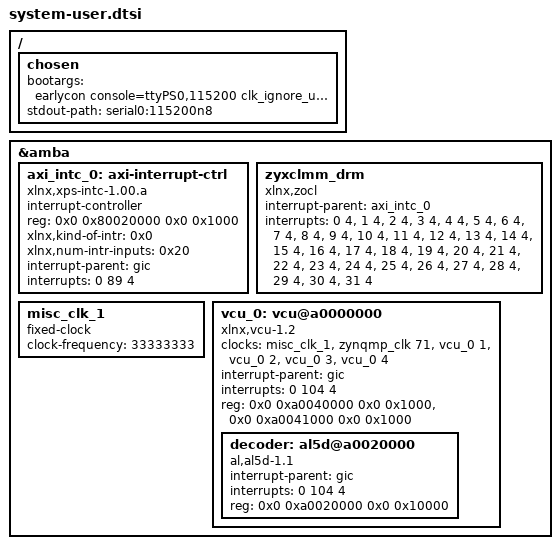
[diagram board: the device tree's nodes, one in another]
/include/ "system-conf.dtsi"
/ {
	chosen {
		bootargs = "earlycon console=ttyPS0,115200 clk_ignore_unused root=/dev/mmcblk0p2 rw rootwait cma=1200M";
		stdout-path = "serial0:115200n8";
	};
};
&amba {
	axi_intc_0: axi-interrupt-ctrl {
		#interrupt-cells = <2>;
		compatible = "xlnx,xps-intc-1.00.a";
		interrupt-controller;
		reg = <0x0 0x80020000 0x0 0x1000>;
		xlnx,kind-of-intr = <0x0>;
		xlnx,num-intr-inputs = <0x20>;
		interrupt-parent = <&gic>;
		interrupts = <0 89 4>;
	};

	zyxclmm_drm {
		compatible = "xlnx,zocl";
		status = "okay";
		interrupt-parent = <&axi_intc_0>;
		interrupts = <0  4>, <1  4>, <2  4>, <3  4>,
			     <4  4>, <5  4>, <6  4>, <7  4>,
			     <8  4>, <9  4>, <10 4>, <11 4>,
			     <12 4>, <13 4>, <14 4>, <15 4>,
			     <16 4>, <17 4>, <18 4>, <19 4>,
			     <20 4>, <21 4>, <22 4>, <23 4>,
			     <24 4>, <25 4>, <26 4>, <27 4>,
			     <28 4>, <29 4>, <30 4>, <31 4>;
	};
	misc_clk_1: misc_clk_1 {
		#clock-cells = <0>;
		clock-frequency = <33333333>;
		compatible = "fixed-clock";
	};

	vcu_0: vcu@a0000000 {
		#clock-cells = <1>;
		#address-cells = <2>;
		#size-cells = <2>;
		clock-names = "pll_ref", "aclk", "vcu_core_enc", "vcu_core_dec", "vcu_mcu_enc", "vcu_mcu_dec";
		clocks = <&misc_clk_1>, <&zynqmp_clk 71>, <&vcu_0 1>, <&vcu_0 2>, <&vcu_0 3>, <&vcu_0 4>;
		compatible = "xlnx,vcu-1.2", "xlnx,vcu";
		interrupt-names = "vcu_host_interrupt";
		interrupt-parent = <&gic>;
		interrupts = <0 104 4>;
		ranges ;
		reg = <0x0 0xa0040000 0x0 0x1000>,
			<0x0 0xa0041000 0x0 0x1000>;
		reg-names = "vcu_slcr", "logicore";
/*
		encoder: al5e@a0100000 {
			compatible = "al,al5e-1.1", "al,al5e";
			interrupt-parent = <&gic>;
			interrupts = <0 96 4>;
			reg = <0x0 0xa0100000 0x0 0x10000>;
		};
*/
		decoder: al5d@a0020000 {
			compatible = "al,al5d-1.1", "al,al5d";
			interrupt-parent = <&gic>;
			interrupts = <0 104 4>;
			reg = <0x0 0xa0020000 0x0 0x10000>;
		};
	};

};
